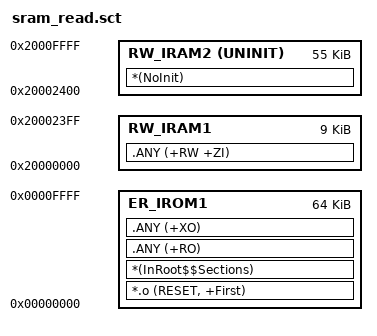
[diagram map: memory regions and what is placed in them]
; *************************************************************
; *** Scatter-Loading Description File generated by uVision ***
; *************************************************************

; new code
#! armcc -E ; new code

LR_IROM1 0x00000000 0x00010000  {    ; load region size_region
  ER_IROM1 0x00000000 0x00010000  {  ; load address = execution address
   *.o (RESET, +First)
   *(InRoot$$Sections)
   .ANY (+RO)
   .ANY (+XO)
  }
  ; modified
  RW_IRAM1 0x20000000 0x00002400  {  ; RW data
   .ANY (+RW +ZI)
  }
  ; new code
  RW_IRAM2 0x20002400 UNINIT 0x0000DC00  { ;no init section
   *(NoInit)
  }
}
